VERSION ""

NS_ :

BS_:

BU_: ACU VCU
VAL_TABLE_ cail 1 "cail" 0 "default" ;
VAL_TABLE_ work_state 1 "工作" 0 "停止" ;

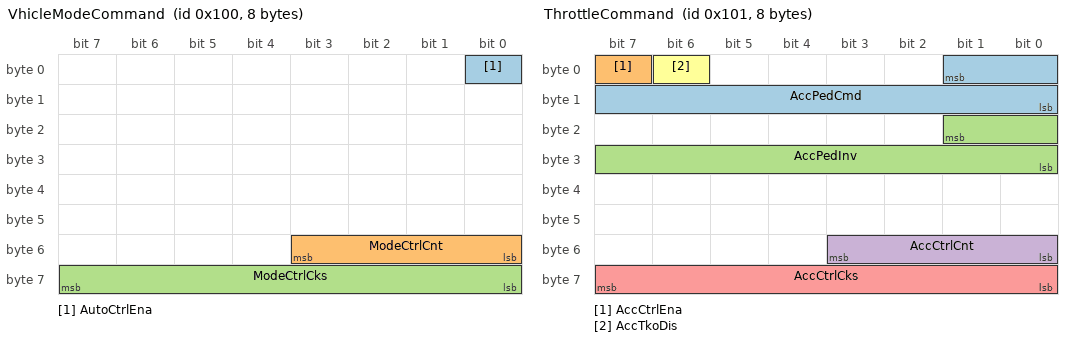
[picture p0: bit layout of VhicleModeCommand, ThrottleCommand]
BO_ 256 VhicleModeCommand: 8 ACU
 SG_ AutoCtrlEna : 0|1@0+ (1,0) [0|1] "-"  VCU
 SG_ ModeCtrlCnt : 51|4@0+ (1,0) [0|15] "-"  VCU
 SG_ ModeCtrlCks : 63|8@0+ (1,0) [0|255] "-"  VCU

BO_ 257 ThrottleCommand: 8 ACU
 SG_ AccPedCmd : 1|10@0+ (0.1,0) [0|100] "%"  VCU
 SG_ AccCtrlEna : 7|1@0+ (1,0) [0|1] "-"  VCU
 SG_ AccPedInv : 17|10@0+ (0.1,0) [0|100] "%"  VCU
 SG_ AccCtrlCnt : 51|4@0+ (1,0) [0|15] "-"  VCU
 SG_ AccCtrlCks : 63|8@0+ (1,0) [0|255] "-"  VCU
 SG_ AccTkoDis : 6|1@0+ (1,0) [0|1] "-"  VCU

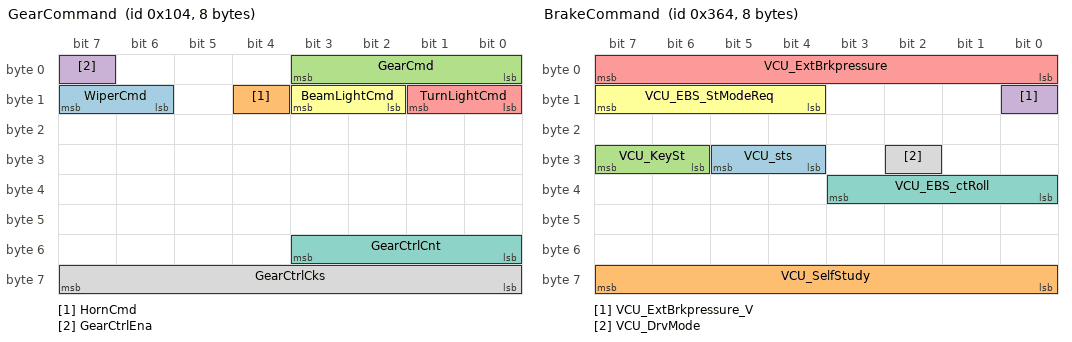
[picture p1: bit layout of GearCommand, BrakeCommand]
BO_ 260 GearCommand: 8 ACU
 SG_ WiperCmd : 15|2@0+ (1,0) [0|3] "" Vector__XXX
 SG_ HornCmd : 12|1@0+ (1,0) [0|1] "-" Vector__XXX
 SG_ GearCmd : 3|4@0+ (1,0) [0|255] "-"  VCU
 SG_ GearCtrlEna : 7|1@0+ (1,0) [0|1] "-"  VCU
 SG_ TurnLightCmd : 9|2@0+ (1,0) [0|3] "-"  VCU
 SG_ BeamLightCmd : 11|2@0+ (1,0) [0|3] "-"  VCU
 SG_ GearCtrlCnt : 51|4@0+ (1,0) [0|15] "-"  VCU
 SG_ GearCtrlCks : 63|8@0+ (1,0) [0|255] "-"  VCU

BO_ 868 BrakeCommand: 8 ACU
 SG_ VCU_sts : 29|2@0+ (1,0) [0|3] "" Vector__XXX
 SG_ VCU_SelfStudy : 63|8@0+ (1,0) [0|255] "" Vector__XXX
 SG_ VCU_KeySt : 31|2@0+ (1,0) [0|3] "" Vector__XXX
 SG_ VCU_ExtBrkpressure_V : 8|1@0+ (1,0) [0|1] "" Vector__XXX
 SG_ VCU_ExtBrkpressure : 7|8@0+ (1,0) [0|125] "Mpa" Vector__XXX
 SG_ VCU_EBS_StModeReq : 15|4@0+ (1,0) [0|14] "" Vector__XXX
 SG_ VCU_EBS_ctRoll : 35|4@0+ (1,0) [0|14] "" Vector__XXX
 SG_ VCU_DrvMode : 26|1@0+ (1,0) [0|1] "" Vector__XXX

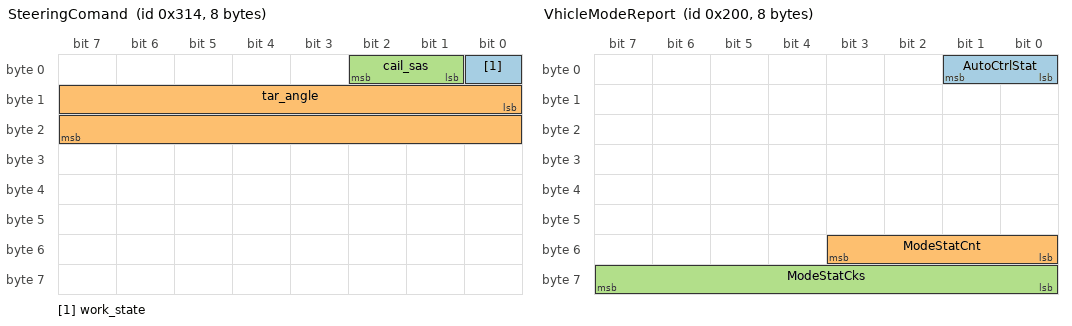
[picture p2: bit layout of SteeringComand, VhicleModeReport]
BO_ 788 SteeringComand: 8 ACU
 SG_ work_state : 0|1@1+ (1,0) [0|1] "" Vector__XXX
 SG_ tar_angle : 8|16@1- (1,0) [-720|720] "" Vector__XXX
 SG_ cail_sas : 1|2@1+ (1,0) [0|1] "" Vector__XXX

BO_ 512 VhicleModeReport: 8 VCU
 SG_ AutoCtrlStat : 1|2@0+ (1,0) [0|3] "-"  ACU
 SG_ ModeStatCnt : 51|4@0+ (1,0) [0|15] "-"  ACU
 SG_ ModeStatCks : 63|8@0+ (1,0) [0|255] "-"  ACU

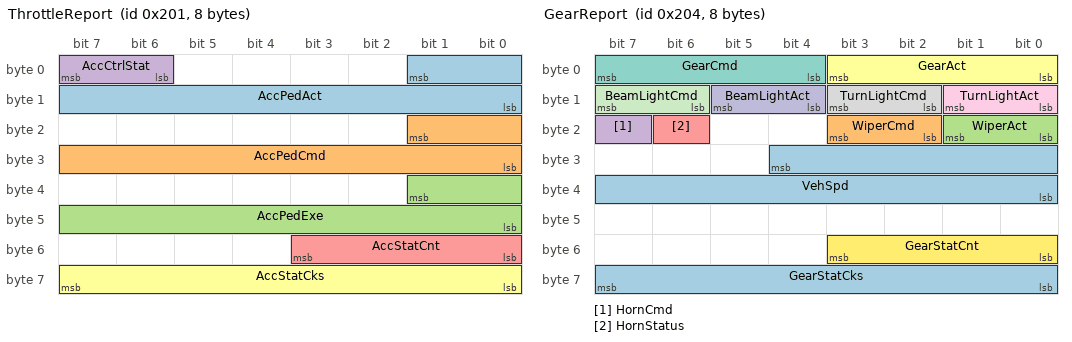
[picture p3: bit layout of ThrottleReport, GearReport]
BO_ 513 ThrottleReport: 8 VCU
 SG_ AccPedAct : 1|10@0+ (0.1,0) [0|100] "%"  ACU
 SG_ AccPedCmd : 17|10@0+ (1,0) [0|255] "-"  ACU
 SG_ AccPedExe : 33|10@0+ (0.1,0) [0|100] "%"  ACU
 SG_ AccCtrlStat : 7|2@0+ (1,0) [0|3] "-"  ACU
 SG_ AccStatCnt : 51|4@0+ (1,0) [0|15] "-"  ACU
 SG_ AccStatCks : 63|8@0+ (1,0) [0|255] "-"  ACU

BO_ 516 GearReport: 8 VCU
 SG_ VehSpd : 28|13@0+ (0.014,0) [0|114.674] "km/h" Vector__XXX
 SG_ WiperCmd : 19|2@0+ (1,0) [0|3] "" Vector__XXX
 SG_ WiperAct : 17|2@0+ (1,0) [0|3] "" Vector__XXX
 SG_ HornCmd : 23|1@0+ (1,0) [0|1] "-" Vector__XXX
 SG_ HornStatus : 22|1@0+ (1,0) [0|1] "-" Vector__XXX
 SG_ GearAct : 3|4@0+ (1,0) [0|5] "-"  ACU
 SG_ GearCmd : 7|4@0+ (1,0) [0|5] "-"  ACU
 SG_ TurnLightCmd : 11|2@0+ (1,0) [0|2] "-"  ACU
 SG_ TurnLightAct : 9|2@0+ (1,0) [0|2] "-"  ACU
 SG_ BeamLightAct : 13|2@0+ (1,0) [0|1] "-"  ACU
 SG_ BeamLightCmd : 15|2@0+ (1,0) [0|1] "-"  ACU
 SG_ GearStatCnt : 51|4@0+ (1,0) [0|15] "-"  ACU
 SG_ GearStatCks : 63|8@0+ (1,0) [0|255] "-"  ACU

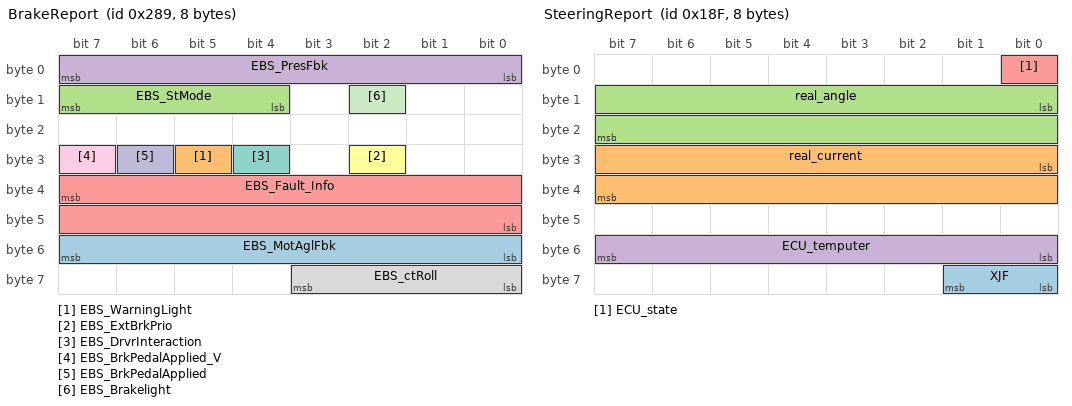
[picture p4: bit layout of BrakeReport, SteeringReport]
BO_ 649 BrakeReport: 8 VCU
 SG_ EBS_MotAglFbk : 55|8@0+ (1,0) [0|255] "" Vector__XXX
 SG_ EBS_WarningLight : 29|1@0+ (1,0) [0|1] "" Vector__XXX
 SG_ EBS_StMode : 15|4@0+ (1,0) [0|14] "" Vector__XXX
 SG_ EBS_PresFbk : 7|8@0+ (1,0) [0|125] "" Vector__XXX
 SG_ EBS_Fault_Info : 39|16@0+ (1,0) [0|65535] "" Vector__XXX
 SG_ EBS_ExtBrkPrio : 26|1@0+ (1,0) [0|1] "" Vector__XXX
 SG_ EBS_DrvrInteraction : 28|1@0+ (1,0) [0|1] "" Vector__XXX
 SG_ EBS_ctRoll : 59|4@0+ (1,0) [0|15] "" Vector__XXX
 SG_ EBS_BrkPedalApplied_V : 31|1@0+ (1,0) [0|1] "" Vector__XXX
 SG_ EBS_BrkPedalApplied : 30|1@0+ (1,0) [0|1] "" Vector__XXX
 SG_ EBS_Brakelight : 10|1@0+ (1,0) [0|1] "" Vector__XXX

BO_ 399 SteeringReport: 8 VCU
 SG_ XJF : 56|2@1+ (1,0) [0|3] "" Vector__XXX
 SG_ real_current : 24|16@1+ (0.001,0) [0|80] "A" Vector__XXX
 SG_ real_angle : 8|16@1- (1,0) [-720|720] "" Vector__XXX
 SG_ ECU_temputer : 48|8@1+ (1,0) [-40|150] "" Vector__XXX
 SG_ ECU_state : 0|1@1+ (1,0) [0|1] "" Vector__XXX

CM_ SG_ 256 AutoCtrlEna "自动控制模式总开关:0=禁用,1=使能。";
CM_ SG_ 256 ModeCtrlCnt "报文计数器。";
CM_ SG_ 256 ModeCtrlCks "报文校验和。";
CM_ SG_ 257 AccPedCmd "加速踏板位置指令,有效范围0~100%。";
CM_ SG_ 257 AccCtrlEna "加速踏板控制使能:0=禁用,1=使能。";
CM_ SG_ 257 AccPedInv "加速踏板位置校验值:有效范围0~100%。";
CM_ SG_ 257 AccCtrlCnt "报文计数器。";
CM_ SG_ 257 AccCtrlCks "报文校验和。";
CM_ SG_ 257 AccTkoDis "-";
CM_ SG_ 260 WiperCmd "雨刮控制指令:0=不开雨刮,1=雨刮低速挡,2=雨刮高速挡,3=雨刮喷水挡。";
CM_ SG_ 260 HornCmd "鸣笛控制指令:0:不鸣笛,1:鸣笛。";
CM_ SG_ 260 GearCmd "档位控制指令:2=R档,3=N档,4=D档,其他保留。";
CM_ SG_ 260 GearCtrlEna "档位控制使能:0=禁用,1=使能。";
CM_ SG_ 260 TurnLightCmd "转向灯控制指令:0=不控制转向灯,1=左转向灯闪烁,2=右转向灯闪烁,3保留。";
CM_ SG_ 260 BeamLightCmd "远近光灯控制指令:0=不开灯,1=开灯,其他:保留。";
CM_ SG_ 260 GearCtrlCnt "报文计数器。";
CM_ SG_ 260 GearCtrlCks "报文校验和。";
CM_ SG_ 512 AutoCtrlStat "自动控制模式状态:0=禁用,1=使能,2=故障,3保留。";
CM_ SG_ 512 ModeStatCnt "报文计数器。";
CM_ SG_ 512 ModeStatCks "报文校验和。";
CM_ SG_ 513 AccPedAct "实际的加速踏板位置:有效范围0~100%。";
CM_ SG_ 513 AccPedCmd "加速踏板位置指令回传:有效范围0~100%。";
CM_ SG_ 513 AccPedExe "执行的加速踏板位置:有效范围0~100%。";
CM_ SG_ 513 AccCtrlStat "驱动控制状态:0=禁用,1=使能,2=故障,3保留。";
CM_ SG_ 513 AccStatCnt "报文计数器。";
CM_ SG_ 513 AccStatCks "报文校验和。";
CM_ SG_ 516 VehSpd "车速。";
CM_ SG_ 516 WiperCmd "雨刮控制指令:0=不开雨刮,1=雨刮低速挡,2=雨刮高速挡,3=雨刮喷水挡。";
CM_ SG_ 516 WiperAct "实际的雨刮状态:0=未开雨刮,1=开启雨刮低速挡,2=开启雨刮高速挡,3=开启雨刮喷水挡。";
CM_ SG_ 516 HornCmd "鸣笛控制指令:0:不鸣笛,1:鸣笛。";
CM_ SG_ 516 HornStatus "鸣笛状态:0=未鸣笛,1=正在鸣笛。";
CM_ SG_ 516 GearAct "实际的档位:2=R档,3=N档,4=D档,其他保留。";
CM_ SG_ 516 GearCmd "档位指令回传:2=R档,3=N档,4=D档,其他保留。";
CM_ SG_ 516 TurnLightCmd "转向灯控制指令回传:0=不控制转向灯,1=左转向灯闪烁,2=右转向灯闪烁,3保留。";
CM_ SG_ 516 TurnLightAct "转向灯状态:0=不控制转向灯,1=左转向灯闪烁,2=右转向灯闪烁,3保留。";
CM_ SG_ 516 BeamLightAct "远近光灯状态:0=灯关闭,1=灯开启,其他:保留。";
CM_ SG_ 516 BeamLightCmd "远近光灯控制指令:0=灯关闭,1=灯开启,其他:保留。";
CM_ SG_ 516 GearStatCnt "报文计数器。";
CM_ SG_ 516 GearStatCks "报文校验和。";
BA_DEF_DEF_  "BusType" "CAN";
BA_DEF_ SG_  "GenSigSendType" ENUM  "Cyclic","OnWrite","OnWriteWithRepetition","OnChange","OnChangeWithRepetition","IfActive","IfActiveWithRepetition","NoSigSendType";
BA_DEF_ SG_  "GenSigStartValue" FLOAT 0 100000000000;
BA_DEF_ BO_  "GenMsgCycleTime" INT 0 10000;
BA_DEF_ BO_  "GenMsgSendType" ENUM  "Cyclic","not_used","not_used","not_used","not_used","Cyclic","not_used","IfActive","NoMsgSendType";
BA_DEF_  "DBName" STRING ;
BA_DEF_  "BusType" STRING ;
BA_DEF_  "BusType" STRING ;
BA_DEF_  "BusType" STRING ;
BA_DEF_DEF_  "BusType" "";
BA_DEF_DEF_  "GenSigSendType" "Cyclic";
BA_DEF_DEF_  "GenSigStartValue" 0;
BA_DEF_DEF_  "GenMsgCycleTime" 0;
BA_DEF_DEF_  "GenMsgSendType" "NoMsgSendType";
BA_DEF_DEF_  "DBName" "";
BA_DEF_DEF_  "BusType" "CAN";
BA_ "BusType" "*";
BA_ "DBName" "CANTemplate";
BA_ "GenMsgSendType" BO_ 256 0;
BA_ "GenMsgCycleTime" BO_ 256 10;
BA_ "GenMsgSendType" BO_ 257 0;
BA_ "GenMsgCycleTime" BO_ 257 10;
BA_ "GenMsgSendType" BO_ 260 0;
BA_ "GenMsgCycleTime" BO_ 260 10;
BA_ "GenMsgSendType" BO_ 512 0;
BA_ "GenMsgCycleTime" BO_ 512 20;
BA_ "GenMsgSendType" BO_ 513 0;
BA_ "GenMsgCycleTime" BO_ 513 20;
BA_ "GenMsgSendType" BO_ 516 0;
BA_ "GenMsgCycleTime" BO_ 516 20;

VAL_ 788 cail_sas 1 "cail" 0 "default" ;
